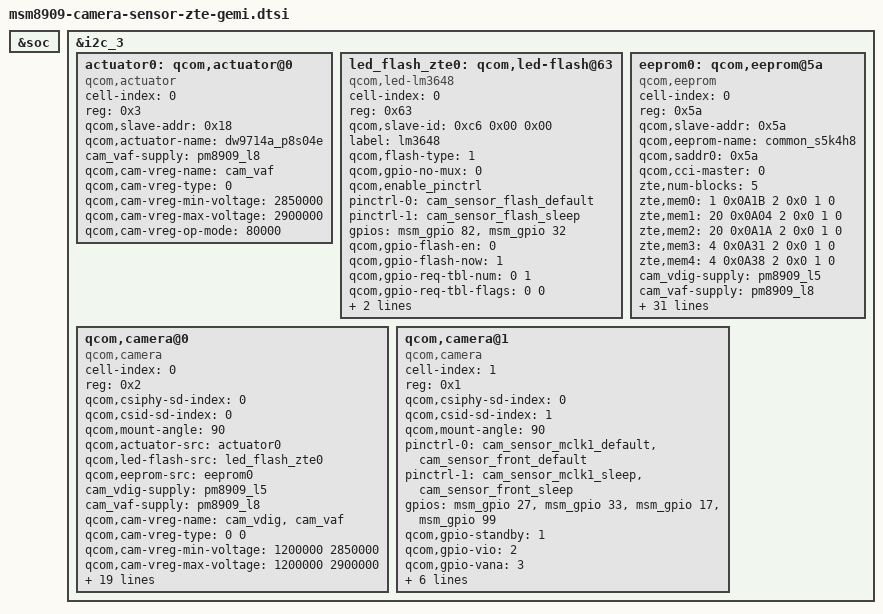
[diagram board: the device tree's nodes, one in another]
/*
 * Copyright (c) 2014-2015, The Linux Foundation. All rights reserved.
 *
 * This program is free software; you can redistribute it and/or modify
 * it under the terms of the GNU General Public License version 2 and
 * only version 2 as published by the Free Software Foundation.
 *
 * This program is distributed in the hope that it will be useful,
 * but WITHOUT ANY WARRANTY; without even the implied warranty of
 * MERCHANTABILITY or FITNESS FOR A PARTICULAR PURPOSE.  See the
 * GNU General Public License for more details.
 */

&soc {
};

&i2c_3 {
	actuator0: qcom,actuator@0 {
		cell-index = <0>;
		reg = <0x3>;
		qcom,slave-addr = <0x18>;
		compatible = "qcom,actuator";
		qcom,actuator-name = "dw9714a_p8s04e";
		/*qcom,cci-master = <0>; */
		cam_vaf-supply = <&pm8909_l8>;
		qcom,cam-vreg-name = "cam_vaf";
		qcom,cam-vreg-type = <0>;
		qcom,cam-vreg-min-voltage = <2850000>;
		qcom,cam-vreg-max-voltage = <2900000>;
		qcom,cam-vreg-op-mode = <80000>;
		status = "ok";
	};

	/* add zte sensor dtsi for led-flash*/
	led_flash_zte0: qcom,led-flash@63 {
		cell-index = <0>;
		reg = <0x63>;
		qcom,slave-id = <0xc6 0x00 0x00>;
		compatible = "qcom,led-lm3648";
		label = "lm3648";
		qcom,flash-type = <1>;
		qcom,gpio-no-mux = <0>;
		qcom,enable_pinctrl;
		pinctrl-names = "cam_flash_default", "cam_flash_suspend";
		pinctrl-0 = <&cam_sensor_flash_default>;
		pinctrl-1 = <&cam_sensor_flash_sleep>;
		gpios = <&msm_gpio 82 0>,
			<&msm_gpio 32 0>;
		qcom,gpio-flash-en = <0>;
		qcom,gpio-flash-now = <1>;
		qcom,gpio-req-tbl-num = <0 1>;
		qcom,gpio-req-tbl-flags = <0 0>;
		qcom,gpio-req-tbl-label = "FLASH_EN",
			"FLASH_NOW";
		qcom,cci-master = <0>;
		status = "ok";
	};

	/*add s5k4h8 eeprom gt24c64a*/
	eeprom0: qcom,eeprom@5a {
		cell-index = <0>;
		reg = <0x5a>;
		qcom,slave-addr = <0x5a>;
		qcom,eeprom-name = "common_s5k4h8";
		compatible = "qcom,eeprom";
		qcom,saddr0 = <0x5a>;
		qcom,cci-master = <0>;
		zte,num-blocks = <5>;
		zte,mem0	= <1 0x0A1B 2 0x0 1 0>; //page 9 lsc group2
		zte,mem1	= <20 0x0A04 2 0x0 1 0>; //page15 awb&mid group1
		zte,mem2	= <20 0x0A1A 2 0x0 1 0>; //page15 awb&mid group1
		zte,mem3	= <4 0x0A31 2 0x0 1 0>; //page15 af group1
		zte,mem4	= <4 0x0A38 2 0x0 1 0>; //page15 af group2
		cam_vdig-supply = <&pm8909_l5>;
		cam_vaf-supply = <&pm8909_l8>;
		qcom,cam-vreg-name = "cam_vdig", "cam_vaf";
		qcom,cam-vreg-type = <0  0>;
		qcom,cam-vreg-min-voltage = <1200000  2850000>;
		qcom,cam-vreg-max-voltage = <1200000  2900000>;
		qcom,cam-vreg-op-mode = <200000  100000>;
		pinctrl-names = "cam_default", "cam_suspend";
		pinctrl-0 = <&cam_sensor_mclk0_default
				&cam_sensor_rear_default>;
		pinctrl-1 = <&cam_sensor_mclk0_sleep &cam_sensor_rear_sleep>;
		gpios = <&msm_gpio 26 0>,
			<&msm_gpio 35 0>,
			<&msm_gpio 17 0>,
			<&msm_gpio 16 0>,
			<&msm_gpio 99 0>;
		qcom,gpio-reset = <1>;
		qcom,gpio-vio = <2>;
		qcom,gpio-vdig = <3>;
		qcom,gpio-vana = <4>;
		qcom,gpio-req-tbl-num = <0 1 2 3 4 >;
		qcom,gpio-req-tbl-flags = <1 0 0 0 0 >;
		qcom,gpio-req-tbl-label = "CAMIF_MCLK",
			"CAM_RESET1",
			"CAM_VIO",
			"CAM_VDIG",
			"CAM_VANA";
		qcom,cam-power-seq-type = "sensor_gpio", "sensor_vreg",
		"sensor_gpio","sensor_gpio","sensor_gpio","sensor_gpio","sensor_clk";
		qcom,cam-power-seq-val ="sensor_gpio_reset","cam_vaf",
		"sensor_gpio_vio", "sensor_gpio_vdig","sensor_gpio_vana","sensor_gpio_reset","sensor_cam_mclk";
		qcom,cam-power-seq-cfg-val = <0 1 1 1 1 1 24000000>;
		qcom,cam-power-seq-delay = <1 1  1 1 1 1 10>;
		status = "ok";
		clocks = <&clock_gcc clk_mclk0_clk_src>,
				<&clock_gcc clk_gcc_camss_mclk0_clk>;
		clock-names = "cam_src_clk", "cam_clk";
	};

	qcom,camera@0 {
		cell-index = <0>;
		compatible = "qcom,camera";
		reg = <0x2>;
		qcom,csiphy-sd-index = <0>;
		qcom,csid-sd-index = <0>;
		qcom,mount-angle = <90>;
		qcom,actuator-src = <&actuator0>;
		qcom,led-flash-src = <&led_flash_zte0>;
		qcom,eeprom-src = <&eeprom0>;
		cam_vdig-supply = <&pm8909_l5>;
		cam_vaf-supply = <&pm8909_l8>;
		qcom,cam-vreg-name = "cam_vdig", "cam_vaf";
		qcom,cam-vreg-type = <0  0>;
		qcom,cam-vreg-min-voltage = <1200000  2850000>;
		qcom,cam-vreg-max-voltage = <1200000  2900000>;
		qcom,cam-vreg-op-mode = <200000  100000>;
		pinctrl-names = "cam_default", "cam_suspend";
		pinctrl-0 = <&cam_sensor_mclk0_default
				&cam_sensor_rear_default>;
		pinctrl-1 = <&cam_sensor_mclk0_sleep &cam_sensor_rear_sleep>;
		gpios = <&msm_gpio 26 0>,
			<&msm_gpio 35 0>,
			<&msm_gpio 17 0>,
			<&msm_gpio 16 0>,
			<&msm_gpio 99 0>;
		qcom,gpio-reset = <1>;
		qcom,gpio-vio = <2>;
		qcom,gpio-vdig = <3>;
		qcom,gpio-vana = <4>;
		qcom,gpio-req-tbl-num = <0 1 2 3 4 >;
		qcom,gpio-req-tbl-flags = <1 0 0 0 0 >;
		qcom,gpio-req-tbl-label = "CAMIF_MCLK",
			"CAM_RESET1",
			"CAM_VIO",
			"CAM_VDIG",
			"CAM_VANA";
		qcom,sensor-position = <0>;
		qcom,sensor-mode = <0>;
		/*qcom,cci-master = <0>;*/
		status = "ok";
		clocks = <&clock_gcc clk_mclk0_clk_src>,
				<&clock_gcc clk_gcc_camss_mclk0_clk>;
		clock-names = "cam_src_clk", "cam_clk";
	};

	qcom,camera@1 {
		cell-index = <1>;
		compatible = "qcom,camera";
		reg = <0x1>;
		qcom,csiphy-sd-index = <0>;
		qcom,csid-sd-index = <1>;
		qcom,mount-angle = <90>;

		pinctrl-names = "cam_default", "cam_suspend";
		pinctrl-0 = <&cam_sensor_mclk1_default &cam_sensor_front_default>;
		pinctrl-1 = <&cam_sensor_mclk1_sleep &cam_sensor_front_sleep>;
		gpios = <&msm_gpio 27 0>,
			<&msm_gpio 33 0>,
			<&msm_gpio 17 0>,
			<&msm_gpio 99 0>;
		qcom,gpio-standby = <1>;
		qcom,gpio-vio = <2>;
		qcom,gpio-vana = <3>;
		qcom,gpio-req-tbl-num = < 0 1 2 3>;
		qcom,gpio-req-tbl-flags = < 0 0 0 0>;
		qcom,gpio-req-tbl-label = "CAMIF_MCLK",
			"CAM_STANDBY",
			"CAM_VIO",
			"CAM_VANA";
		status = "ok";
		clocks = <&clock_gcc clk_mclk1_clk_src>,
				<&clock_gcc clk_gcc_camss_mclk1_clk>;
		clock-names = "cam_src_clk", "cam_clk";
	};
};
